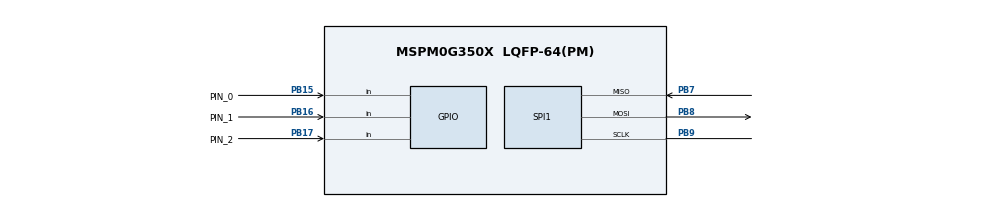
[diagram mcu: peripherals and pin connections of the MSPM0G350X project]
/**
 * @cliArgs --device "MSPM0G350X" --package "LQFP-64(PM)" --part "Default" --product "mspm0_sdk@2.00.01.00"
 * @versions {"tool":"1.20.0+3587"}
 */

/**
 * Import the modules used in this configuration.
 */
const GPIO   = scripting.addModule("/ti/driverlib/GPIO", {}, false);
const GPIO1  = GPIO.addInstance();
const SPI    = scripting.addModule("/ti/driverlib/SPI", {}, false);
const SPI1   = SPI.addInstance();
const SYSCTL = scripting.addModule("/ti/driverlib/SYSCTL");

/**
 * Write custom configuration values to the imported modules.
 */
GPIO1.$name                                 = "GPIO_GRP_0";
GPIO1.associatedPins.create(3);
GPIO1.associatedPins[0].$name               = "PIN_0";
GPIO1.associatedPins[0].direction           = "INPUT";
GPIO1.associatedPins[0].assignedPort        = "PORTB";
GPIO1.associatedPins[0].assignedPortSegment = "Lower";
GPIO1.associatedPins[0].assignedPin         = "15";
GPIO1.associatedPins[0].polarity            = "RISE";
GPIO1.associatedPins[0].internalResistor    = "PULL_UP";
GPIO1.associatedPins[0].pin.$assign         = "PB15";
GPIO1.associatedPins[1].$name               = "PIN_1";
GPIO1.associatedPins[1].direction           = "INPUT";
GPIO1.associatedPins[1].assignedPort        = "PORTB";
GPIO1.associatedPins[1].assignedPortSegment = "Upper";
GPIO1.associatedPins[1].assignedPin         = "16";
GPIO1.associatedPins[1].internalResistor    = "PULL_UP";
GPIO1.associatedPins[1].pin.$assign         = "PB16";
GPIO1.associatedPins[2].$name               = "PIN_2";
GPIO1.associatedPins[2].direction           = "INPUT";
GPIO1.associatedPins[2].assignedPort        = "PORTB";
GPIO1.associatedPins[2].assignedPortSegment = "Upper";
GPIO1.associatedPins[2].assignedPin         = "17";
GPIO1.associatedPins[2].internalResistor    = "PULL_UP";
GPIO1.associatedPins[2].pin.$assign         = "PB17";

const Board = scripting.addModule("/ti/driverlib/Board", {}, false);

SPI1.$name                              = "SPI1";
SPI1.targetBitRate                      = 800000;
SPI1.frameFormat                        = "MOTO3";
SPI1.peripheral.$assign                 = "SPI1";
SPI1.peripheral.sclkPin.$assign         = "PB9";
SPI1.peripheral.mosiPin.$assign         = "PB8";
SPI1.peripheral.misoPin.$assign         = "PB7";
SPI1.sclkPinConfig.$name                = "ti_driverlib_gpio_GPIOPinGeneric0";
SPI1.sclkPinConfig.direction            = scripting.forceWrite("OUTPUT");
SPI1.sclkPinConfig.onlyInternalResistor = scripting.forceWrite(false);
SPI1.sclkPinConfig.passedPeripheralType = scripting.forceWrite("Digital");
SPI1.mosiPinConfig.$name                = "ti_driverlib_gpio_GPIOPinGeneric1";
SPI1.mosiPinConfig.direction            = scripting.forceWrite("OUTPUT");
SPI1.mosiPinConfig.hideOutputInversion  = scripting.forceWrite(false);
SPI1.mosiPinConfig.onlyInternalResistor = scripting.forceWrite(false);
SPI1.mosiPinConfig.passedPeripheralType = scripting.forceWrite("Digital");
SPI1.misoPinConfig.$name                = "ti_driverlib_gpio_GPIOPinGeneric2";
SPI1.misoPinConfig.onlyInternalResistor = scripting.forceWrite(false);
SPI1.misoPinConfig.passedPeripheralType = scripting.forceWrite("Digital");

SYSCTL.forceDefaultClkConfig = true;

/**
 * Pinmux solution for unlocked pins/peripherals. This ensures that minor changes to the automatic solver in a future
 * version of the tool will not impact the pinmux you originally saw.  These lines can be completely deleted in order to
 * re-solve from scratch.
 */
Board.peripheral.$suggestSolution          = "DEBUGSS";
Board.peripheral.swclkPin.$suggestSolution = "PA20";
Board.peripheral.swdioPin.$suggestSolution = "PA19";
SYSCTL.peripheral.$suggestSolution         = "SYSCTL";
